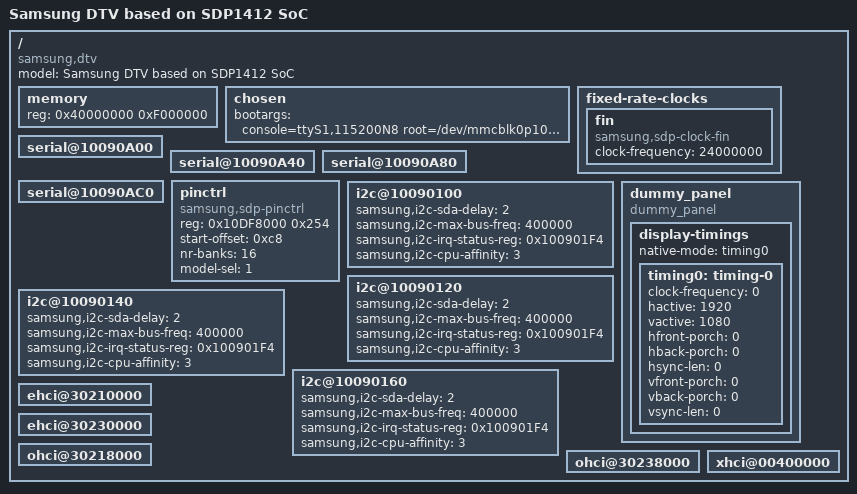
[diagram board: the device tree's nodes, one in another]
/*
 * Copyright (C) 2014 Samsung Electronics Co.Ltd
 *
 * This program is free software; you can redistribute it and/or modify
 * it under the terms of the GNU General Public License version 2 as
 * published by the Free Software Foundation.
 */

/dts-v1/;
/include/ "sdp1412.dtsi"

/ {
	model = "Samsung DTV based on SDP1412 SoC";
	compatible = "samsung,dtv", "samsung,sdp1412";

	memory {
		device_type = "memory";
		reg =  <0x40000000 0xF000000>;
	};

	chosen {
		bootargs = "console=ttyS1,115200N8 root=/dev/mmcblk0p10  SELP_ENABLE=00000000 rootfstype=squashfs rootwait earlyprintk nosmp";
		//bootargs = "console=ttyS0,115200N8 root=/dev/ram0 initrd=0x50800000,32M rootwait earlyprintk nosmp";
	};

	fixed-rate-clocks {
		fin {
			compatible = "samsung,sdp-clock-fin";
			clock-frequency = <24000000>;
		};
	};

	serial@10090A00 {
		status = "okay";
	};

	serial@10090A40 {
		status = "okay";
	};

	serial@10090A80 {
		status = "okay";
	};

	serial@10090AC0 {
		status = "okay";
	};


	pinctrl{
		compatible = "samsung,sdp-pinctrl";
		reg = <0x10DF8000 0x254>;
		start-offset = <0xc8>;
		nr-banks = <16>;	
		model-sel = <1>;	
	};

	i2c@10090100 {
		status = "okay";
		samsung,i2c-sda-delay = <2>;
		samsung,i2c-max-bus-freq = <400000>;
		samsung,i2c-irq-status-reg = <0x100901F4>;
		samsung,i2c-cpu-affinity = <3>;
	};

	i2c@10090120 {
		status = "okay";
		samsung,i2c-sda-delay = <2>;
		samsung,i2c-max-bus-freq = <400000>;
		samsung,i2c-irq-status-reg = <0x100901F4>;
		samsung,i2c-cpu-affinity = <3>;
	};

	i2c@10090140 { 
		status = "okay";
		samsung,i2c-sda-delay = <2>;
		samsung,i2c-max-bus-freq = <400000>;
		samsung,i2c-irq-status-reg = <0x100901F4>;
		samsung,i2c-cpu-affinity = <3>;
	};

	i2c@10090160 {
		status = "okay";
		samsung,i2c-sda-delay = <2>;
		samsung,i2c-max-bus-freq = <400000>;
		samsung,i2c-irq-status-reg = <0x100901F4>;
		samsung,i2c-cpu-affinity = <3>;
	};

	dummy_panel {                          
			compatible = "dummy_panel";    

			display-timings {              
				native-mode = <&timing0>;  

				timing0: timing-0 {        
								 clock-frequency = <0>; 
								 hactive = <1920>;      
								 vactive = <1080>;      
								 hfront-porch = <0>;    
								 hback-porch = <0>;     
								 hsync-len = <0>;       
								 vfront-porch = <0>;    
								 vback-porch = <0>;     
								 vsync-len = <0>;       
		 	};                             
		};                                 

	};

	ehci@30210000 {
		status = "okay";
	};

       ehci@30230000 {
		status = "okay";
	};
	
	ohci@30218000 {
		status = "okay";
	};

	ohci@30238000 {
		status = "okay";
	};
	
	xhci@00400000 {
		status = "okay";
	};
/*
	thermal@005c1070 {
		status = "okay";
		compatible = "samsung,sdp-thermal";

		reg = <0x005c1070 0x30>;

		start_cold_throttle	= <40>;
		stop_cold_throttle	= <45>;
		stop_1st_throttle	= <102>;
		start_1st_throttle	= <110>;
		stop_2nd_throttle	= <112>;
		start_2nd_throttle	= <118>;
		stop_3rd_throttle	= <120>;
		start_3rd_throttle	= <125>;
		start_3rd_hotplug	= <130>;

		cpu_limit_1st_throttle	= <1000000>;
		cpu_limit_2nd_throttle	= <700000>;
		cpu_limit_3rd_throttle	= <100000>;

		gpu_limit_1st_throttle	= <200000>;
		gpu_limit_2nd_throttle	= <200000>;
		gpu_limit_3rd_throttle	= <100000>;

		log_file_path = "/rwarea/ThermalThrottle.txt";
	};

*/

};
